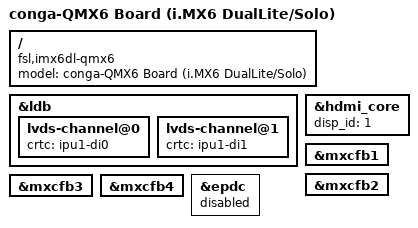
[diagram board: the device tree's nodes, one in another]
/*
 * Copyright 2015 congatec AG
 * Copyright 2012 Freescale Semiconductor, Inc.
 * Copyright 2011 Linaro Ltd.
 *
 * The code contained herein is licensed under the GNU General Public
 * License. You may obtain a copy of the GNU General Public License
 * Version 2 or later at the following locations:
 *
 * http://www.opensource.org/licenses/gpl-license.html
 * http://www.gnu.org/copyleft/gpl.html
 */

/dts-v1/;

#include "imx6dl.dtsi"
#include "imx6qdl-qmx6.dtsi"

/ {
	model = "conga-QMX6 Board (i.MX6 DualLite/Solo)";
	compatible = "fsl,imx6dl-qmx6", "fsl,imx6dl";
};

&ldb {
	lvds-channel@0 {
		crtc = "ipu1-di0";
	};

	lvds-channel@1 {
		crtc = "ipu1-di1";
	};
};

&hdmi_core {
	disp_id = <1>;
	status = "okay";
};

&mxcfb1 {
	status = "okay";
};

&mxcfb2 {
	status = "okay";
};

&mxcfb3 {
	status = "okay";
};

&mxcfb4 {
	status = "okay";
};


&epdc {
	status = "disabled";
};
